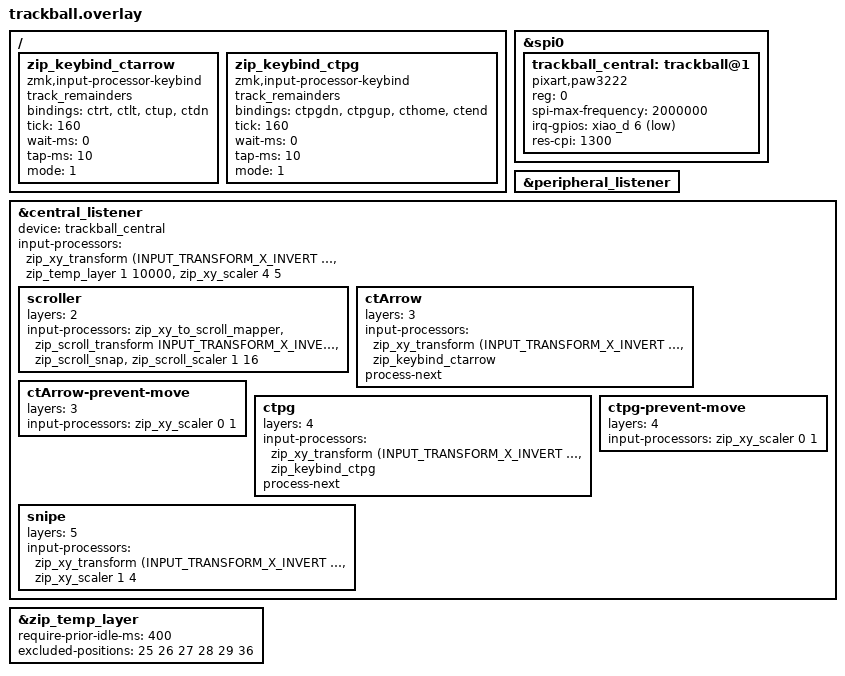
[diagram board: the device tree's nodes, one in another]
#include <input/processors/zmk-input-processor-keybind.dtsi>
#include <zephyr/dt-bindings/input/input-event-codes.h>
#include <scroll-snap.dtsi>
&spi0 {
    status = "okay";
    trackball_central: trackball@1 {
        status = "okay";
        compatible = "pixart,paw3222";
        reg = <0>;
        spi-max-frequency = <2000000>;
        irq-gpios = <&xiao_d 6 (GPIO_ACTIVE_LOW | GPIO_PULL_UP)>;
        res-cpi = <1300>;
    };
};
/ {
    zip_keybind_ctarrow: zip_keybind_ctarrow {
        compatible = "zmk,input-processor-keybind";
        #input-processor-cells = <0>;
        track_remainders;
        bindings = <&ctrt>,
                  <&ctlt>,
                  <&ctup>,
                  <&ctdn>;
        tick = <160>;
        wait-ms = <0>;
        tap-ms = <10>;
         mode = <1>;
        // threshold = <10>
        // max_threshold = <200>
        // max_pending_activations = <10>
    };
     zip_keybind_ctpg: zip_keybind_ctpg {
        compatible = "zmk,input-processor-keybind";
        #input-processor-cells = <0>;
        track_remainders;
        bindings = <&ctpgdn>,
                  <&ctpgup>,
                  <&cthome>,
                  <&ctend>;
        tick = <160>;
        wait-ms = <0>;
        tap-ms = <10>;
         mode = <1>;
        // threshold = <10>
        // max_threshold = <200>
        // max_pending_activations = <10>
    };
 //  input_processors {
   //     zip_scroll_x_scaler: zip_scroll_x_scaler {
   //         compatible = "zmk,input-processor-scaler";
   //         #input-processor-cells = <2>;
   //         type = <INPUT_EV_REL>;
   //         codes = <INPUT_REL_HWHEEL>;
   //         track-remainders;
   //     };
   // };

};
// ペリフェラル（split経由）のリスナーを有効化
&peripheral_listener {
    status = "okay";
     /* input-processors =
        <&zip_xy_scaler 1 5>;
    };
    arrow {
            layers = <0>;
            input-processors =
            <&zip_keybind_keys>;
             process-next;
    };

    arrow-prevent-move {
        layers = <0>;
        input-processors = <&zip_xy_scaler 0 1>;
    };*/  
};  

// セントラルのリスナーを有効化し、deviceを紐付け
&central_listener {
    status = "okay";
    device = <&trackball_central>;
    input-processors = 
        <&zip_xy_transform (INPUT_TRANSFORM_X_INVERT | INPUT_TRANSFORM_Y_INVERT)
        &zip_temp_layer 1 10000
        &zip_xy_scaler 4 5>;

     scroller {
        layers = <2>;
        input-processors = 
            <&zip_xy_to_scroll_mapper>,
            <&zip_scroll_transform INPUT_TRANSFORM_X_INVERT>,
            <&zip_scroll_snap>,
            <&zip_scroll_scaler 1 16>;
    };

    ctArrow{
        layers = <3>;
        input-processors =
            <&zip_xy_transform (INPUT_TRANSFORM_X_INVERT | INPUT_TRANSFORM_Y_INVERT)
             &zip_keybind_ctarrow>;
             process-next;
    };

    ctArrow-prevent-move {
        layers = <3>;
        input-processors = <&zip_xy_scaler 0 1>;
    };

    ctpg{
        layers = <4>;
        input-processors =
            <&zip_xy_transform (INPUT_TRANSFORM_X_INVERT | INPUT_TRANSFORM_Y_INVERT)
             &zip_keybind_ctpg>;
             process-next;
    };

    ctpg-prevent-move {
        layers = <4>;
        input-processors = <&zip_xy_scaler 0 1>;
    };
    
    snipe {
        layers = <5>; 
        input-processors = 
            <&zip_xy_transform (INPUT_TRANSFORM_X_INVERT | INPUT_TRANSFORM_Y_INVERT)
             &zip_xy_scaler 1 4>;
         };
};

&zip_temp_layer {
    require-prior-idle-ms = <400>;

    excluded-positions = <
       //   5 6 7 8 9
       // 10 11 12 13 14 15 16 17 18 19
          25 26 27 28 29
          36
    >;
}; 
